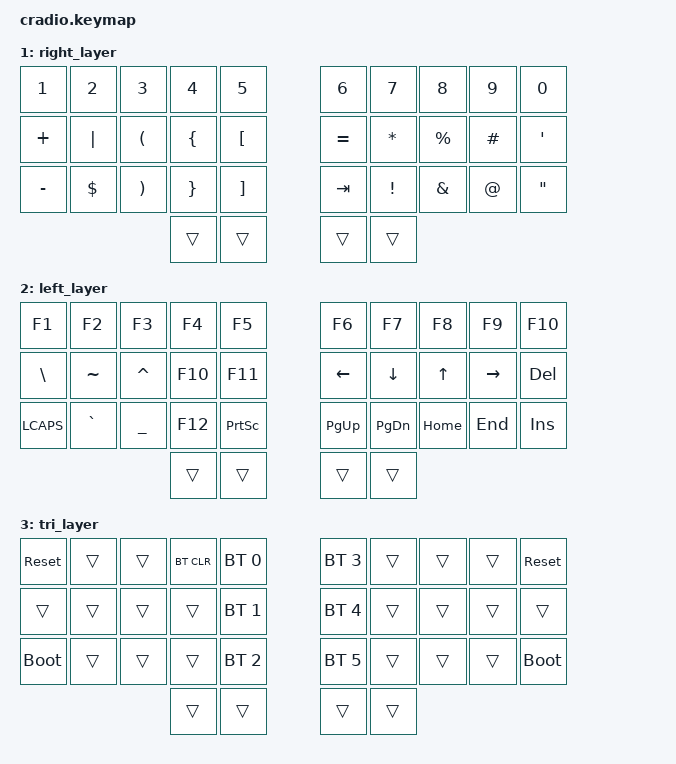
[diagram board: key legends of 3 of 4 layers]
// Copyright (c) 2022 The ZMK Contributors
// SPDX-License-Identifier: MIT

#include <behaviors.dtsi>
#include <dt-bindings/zmk/keys.h>
#include <dt-bindings/zmk/bt.h>

// Home row mods macro
#define HRML(k1,k2,k3,k4) &ht LSHFT k1  &ht LALT k2  &ht LCTRL k3  &ht LGUI k4
#define HRMR(k1,k2,k3,k4) &ht RGUI k1  &ht RCTRL k2  &ht RALT k3  &ht RSHFT k4

/ {
    behaviors {
        ht: hold_tap {
            label = "hold_tap";
            compatible = "zmk,behavior-hold-tap";
            #binding-cells = <2>;
            flavor = "tap-preferred";
            tapping-term-ms = <220>;
            quick-tap-ms = <150>;
            require-prior-idle-ms = <100>;
            bindings = <&kp>, <&kp>;
        };
    };

    conditional_layers {
        compatible = "zmk,conditional-layers";
        tri_layer {
            if-layers = <1 2>;
            then-layer = <3>;
        };
    };

    keymap {
        compatible = "zmk,keymap";
        default_layer {
            bindings = <
        //╭──────────┬──────────┬──────────┬──────────┬──────────╮   ╭──────────┬──────────┬──────────┬──────────┬──────────╮
        //│  Q       │  W       │  E       │  R       │  T       │   │  Y       │  U       │  I       │  O       │  P       │
            &kp Q      &kp W      &kp E      &kp R      &kp T          &kp Y      &kp U      &kp I      &kp O      &kp P
        //├──────────┼──────────┼──────────┼──────────┼──────────┤   ├──────────┼──────────┼──────────┼──────────┼──────────┤
        //│  A       │  S       │  D       │  F       │  G       │   │  H       │  J       │  K       │  L       │ ; :      │
            &kp A      &kp S      &kp D      &kp F      &kp G          &kp H      &kp J      &kp K      &kp L      &kp SEMI
        //├──────────┼──────────┼──────────┼──────────┼──────────┤   ├──────────┼──────────┼──────────┼──────────┼──────────┤
        //│  Z       │  X       │  C       │  V       │  B       │   │  N       │  M       │ , <      │ . >      │ / ?      │
            HRML(Z,        X,         C,         V)    &kp B          &kp N      HRMR(M,     COMMA,     DOT,         FSLH)
        //╰──────────┴──────────┴──────────┼──────────┼──────────┤   ├──────────┼──────────┼──────────┴──────────┴──────────╯
                                            &lt 1 ENTER &kp SPACE     &kp BSPC   &lt 2 ESC
        //                                 ╰──────────┴──────────╯   ╰──────────┴──────────╯
            >;
        };

        right_layer {
            bindings = <
        //╭──────────┬──────────┬──────────┬──────────┬──────────╮   ╭──────────┬──────────┬──────────┬──────────┬──────────╮
        //│    1     │  2       │  3       │  4       │  5       │   │  6       │  7       │  8       │  9       │  0       │
            &kp N1     &kp N2     &kp N3     &kp N4     &kp N5         &kp N6     &kp N7     &kp N8     &kp N9     &kp N0 
        //├──────────┼──────────┼──────────┼──────────┼──────────┤   ├──────────┼──────────┼──────────┼──────────┼──────────┤
        //│  +       │  |       │  (       │  {       │  [       │   │  =       │  *       │  %       │  #          '       │
            &kp PLUS   &kp PIPE   &kp LPAR   &kp LBRC   &kp LBKT       &kp EQUAL  &kp ASTRK  &kp PRCNT  &kp HASH   &kp SQT
        //├──────────┼──────────┼──────────┼──────────┼──────────┤   ├──────────┼──────────┼──────────┼──────────┼──────────┤
        //│  -       │  $       │  )       │  }       │  ]       │   │  TAB     │  !       │  &       │  @       │  "       │
            &kp MINUS  &kp DLLR   &kp RPAR   &kp RBRC   &kp RBKT       &kp TAB    &kp EXCL   &kp AMPS   &kp AT     &kp DQT
        //╰──────────┴──────────┴──────────┼──────────┼──────────┤   ├──────────┼──────────┼──────────┴──────────┴──────────╯
                                             &trans     &trans         &trans     &trans
        //                                 ╰──────────┴──────────╯   ╰──────────┴──────────╯
            >;
        };

        left_layer {
            bindings = <
        //╭──────────┬──────────┬──────────┬──────────┬──────────╮   ╭──────────┬──────────┬──────────┬──────────┬──────────╮
        //│  F1      │  F2      │  F3      │  F4      │  F5      │   │  F6      │  F7      │  F8      │  F9      │  F10     │
            &kp F1     &kp F2     &kp F3     &kp F4     &kp F5         &kp F6     &kp F7     &kp F8     &kp F9     &kp F10
        //├──────────┼──────────┼──────────┼──────────┼──────────┤   ├──────────┼──────────┼──────────┼──────────┼──────────┤
        //│  \       │  ~       │  ^       │  F10     │  F11     │   │  LEFT    │  DOWN    │  UP      │  RIGHT   │  DELETE  │
            &kp BSLH   &kp TILDE  &kp CARET  &kp F10    &kp F11        &kp LEFT   &kp DOWN   &kp UP     &kp RIGHT  &kp DEL
        //├──────────┼──────────┼──────────┼──────────┼──────────┤   ├──────────┼──────────┼──────────┼──────────┼──────────┤
        //│  CAPS    │  `       │  _       │  F12     │  PrtScr  │   │  PAGE UP │  PAGEDWN │  HOME    │  END     │  INSERT  │
            &kp LCAPS  &kp GRAVE  &kp UNDER  &kp F12    &kp PSCRN      &kp PG_UP  &kp PG_DN  &kp HOME   &kp END    &kp INS  
        //╰──────────┴──────────┴──────────┼──────────┼──────────┤   ├──────────┼──────────┼──────────┴──────────┴──────────╯
                                             &trans     &trans         &trans     &trans
        //                                 ╰──────────┴──────────╯   ╰──────────┴──────────╯
            >;
        };


        //│          │          │          │          │          │   │          │          │          │          │          │
//            &kp        &kp        &kp        &kp        &kp            &kp        &kp        &kp        &kp        &kp  


        tri_layer {
            bindings = <
        //╭──────────┬──────────┬──────────┬──────────┬──────────╮   ┬──────────┬──────────┬──────────┬──────────┬──────────╮
        //│ RESET    │          │          │ CLEAR BT │PROFILE 0 │   │PROFILE 3 │          │          │          │  RESET   │
           &sys_reset  &trans     &trans    &bt BT_CLR &bt BT_SEL 0   &bt BT_SEL 3 &trans    &trans     &trans    &sys_reset
        //├──────────┼──────────┼──────────┼──────────┼──────────┤   ┼──────────┼──────────┼──────────┼──────────┼──────────┤
        //│          │          │          │          │PROFILE 1 │   │PROFILE 4 │          │          │          │          │
            &trans     &trans     &trans     &trans    &bt BT_SEL 1   &bt BT_SEL 4 &trans    &trans     &trans     &trans
        //├──────────┼──────────┼──────────┼──────────┼──────────┤   ┼──────────┼──────────┼──────────┼──────────┼──────────┤
        //│BOOTLOADER│          │          │          │PROFILE 2 │   │PROFILE 5 │          │          │          │BOOTLOADER│
          &bootloader  &trans     &trans     &trans    &bt BT_SEL 2   &bt BT_SEL 5 &trans    &trans     &trans   &bootloader
        //╰──────────┴──────────┴──────────┼──────────┼──────────┤   ┼──────────┼──────────┼──────────┴──────────┴──────────╯
                                             &trans     &trans         &trans     &trans
        //                                 ╰──────────┴──────────╯   ╰──────────┴──────────╯
            >;
        };
    };
};
